# rCSL_sata_001 register map
Vendor: Texas Instruments
Peripheral module from a debugger description file (folder OMAPL138_C6748).
Registers are 32-bit, access not given, reset 0x0 unless marked. A register's access mark holds for its fields unless they carry their own. Offsets are as the file gives them; lines under a group give offsets from that group; [hi:lo] are bit positions; {n}, {i} and the like mark numbered series; 'fields as' and 'values as' point back to an identical list; <NAME> marks a mode.

## SATA (part 1 of 2) — SATA Interface Controller
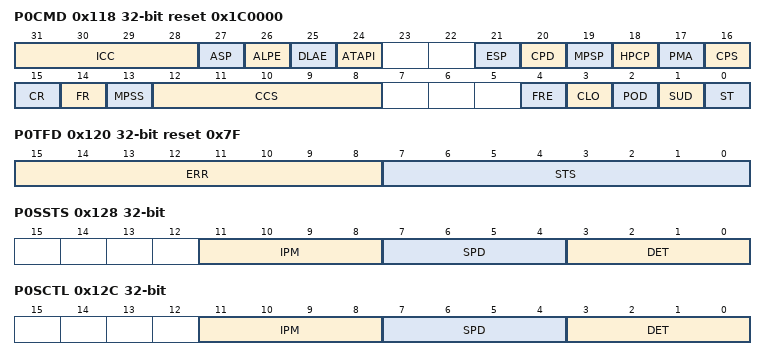
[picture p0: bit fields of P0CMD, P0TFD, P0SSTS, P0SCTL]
0x118 P0CMD reset 0x1C0000 — This register contains bits controlling various Port functions. All RW bits are reset on Global reset.
  [31:28] ICC rw — Interface Communication Control. This field is used to control power management states of the interface. If the Link layer is currently in the L_IDLE state, writes to this field will cause the Port to initiate a transition to the interface power management state requested. If the Link layer is not currently in the L_IDLE state, writes to this field have no effect. " 0xF - 0x7: Reserved " 0x6: Slumber: This will cause the Port to request a transition of the interface to the Slumber state. The SATA device may reject the request and the interface will remain in its current state. " 0x5 - 0x3: Reserved " 0x2: Partial: This will cause the Port to request a transition of the interface to the Partial state. The SATA device may reject the request and the interface will remain in its current state. " 0x1: Active: This will cause the Port to request a transition of the interface into the active state. " 0x0: No-Op/ Idle: When software reads this value, it indicates the Port is ready to accept a new interface control command, although the transition to the previously selected state may not yet have occurred. When system software writes a non-reserved value other than No-Op (0x0), the Port will perform the action and update this field back to Idle (0x0). If software writes to this field to change the state to a state the link is already in (i.e., interface is in the active state and a request is made to go to the active state), the Port will take no action and return this field to Idle. If the interface is in a low power state and software wants to transition to a different low power state, software must first bring the link to active and then initiate the transition to the desired low power
  [27] ASP rw — Aggressive Slumber/Partial. When set to 1, and P0CMD.ALPE=1, the Port will aggressively enter the SLUBMER state when it clears the P0CI and the P0SACT register is cleared or when it clears the P0SACT register and P0CI is cleared. When cleared to 0, and P0CMD.ALPE=1, the Port will aggressively enter the PARTIAL state when it clears the P0CI register and the P0SACT register is cleared when it clears the P0SACT register and P0CI is cleared.
  [26] ALPE rw — Aggressive Link Power Management Enable. When set to 1, the Port will aggressively enter a lower link power state (PARTIAL or SLUMBER) based on the setting of the P#CMD.ASP bit. When cleared to 0, aggressive power management state transition is disabled.
  [25] DLAE rw — Device LED on ATAPI Enable. When set to 1 , the HBA shall drive the LED pin active for commands regardless of the state of P0CMD.ATAPI. When cleared, the HBA shall only drive the LED pin active for commands if P0CMD.ATAPI set to 0 .
  [24] ATAPI rw — Device is ATAPI. When set to '1', the connected device is an ATAPI device. This bit is used by the HBA to control whether or not to generate the desktop LED when commands are active.
  [21] ESP ro — External SATA Port. When set to '1', indicates that this port s signal connector is externally accessible on a signal only connector. When set to '1', CAP.SXS shall be set to '1'. When cleared to 0 , indicates that this port s signal connector is not externally accessible on a signal only connector. ESP is mutually exclusive with the HPCP bit in this register.
  [20] CPD ro — Cold Presence Detection. If set to 1 , the platform supports cold presence detection on this port. If cleared to 0 , the platform does not support cold presence detection on this port. When tis bit is set to '1', P0CMD.HPCP should also be '1'.
  [19] MPSP ro — Mechanical Presence Switch Attached to Port. If set to 1 , the platform supports an mechanical presence switch attached to this port. If cleared to 0 , the platform does not support a mechanical presence switch attached to this port. When this bit is set to 1 , P0CMD.HPCP should also be set to '1'.
  [18] HPCP ro — Hot Plug Capable Port. When set to 1 , indicates that this port s signal and power connectors are externally accessible via a joint signal and power connector for blindmate device hot plug. When cleared to 0 , indicates that this port s signal and power connectors are not externally accessible via a joint signal and power connector.
  [17] PMA rw — Port Multiplier Attached: When set to 1 by software, a Port Multiplier is attached to the HBA for this port. When cleared to 0 by software, a Port Multiplier is not attached to the HBA for this port. Software is responsible for detecting whether a Port Multiplier is present; hardware does not auto-detect the presence of a Port Multiplier.
  [16] CPS ro — Cold Presence State. The CPS bit reports whether a device is currently detected on this port via cold presence detection. If CPS is set to 1 , then the HBA detects via cold presence that a device is attached to this port. If CPS is cleared to 0 , then the HBA detects via cold presence that there is no device attached to this port.
  [15] CR ro — Command List Running. When this bit is set, the command list DMA engine for the port is running.
  [14] FR ro — FIS Receive Running. When this bit is set, the command list DMA engine for the port is running.
  [13] MPSS ro — Mechanical Presence Switch State. The MPSS bit reports the state of a mechanical presence switch attached to this port. If CAP.SMPS is set to 1 and the mechanical presence switch is closed then this bit is cleared to 0 . If CAP.SMPS is set to 1 and the mechanical presence switch is open then this bit is set to 1 . If CAP.SMPS is set to 0 then this bit is cleared to 0 . Software should only use this bit if both CAP.SMPS and P0CMD.MPSP are set to 1'.
  [12:8] CCS ro — Current Command Slot. This field is valid when P0CMD.ST is set to 1 and shall be set to the command slot value of the command that is currently being issued by the HBA. When P0CMD.ST transitions from 1 to 0 , this field shall be reset to 0 . After P0CMD.ST transitions from 0 to 1 , the highest priority slot to issue from next is command slot 0. After the first command has been issued, the highest priority slot to issue from next is P0CMD.CCS + 1. For example, after the HBA has issued its first command, if CCS = 0h and P0CI is set to 3h, the next command that will be issued is from command slot 1.
  [4] FRE rw — FIS Receive Enable. When set, the HBA may post received FISes into the FIS receive area pointed to by P0FB. When cleared, received FISes are not accepted by the HBA, except for the first D2H register FIS after the initialization sequence, and no FISes are posted to the FIS receive area. System software must not set this bit until P0FB have been programmed with a valid pointer to the FIS receive area, and if software wishes to move the base, this bit must first be cleared, and software must wait for the FR bit in this register to be cleared.
  [3] CLO rw — Command List Override. Setting this bit to 1 causes P0TFD.STS.BSY and PxTFD.STS.DRQ to be cleared to 0 . This allows a software reset to be transmitted to the device regardless of whether the BSY and DRQ bits are still set in the P0TFD.STS register. The HBA sets this bit to 0 when P0TFD.STS.BSY and P0TFD.STS.DRQ have been cleared to 0 . A write to this register with a value of 0 shall have no effect. This bit shall only be set to 1 immediately prior to setting the P0CMD.ST bit to 1 from a previous value of 0 . Setting this bit to 1 at any other time is not supported and will result in indeterminate behavior. Software must wait for CLO to be cleared to 0 before setting P0CMD.ST to 1 .
  [2] POD rw — Power On Device. When set, the HBA sets the state of a pin on the HBA to 1 so that it may be used to provide power to a cold-presence detectable port
  [1] SUD rw — Spin-Up Device. On an edge detect from 0 to 1 , the HBA shall start a COMRESET initializatoin sequence to the device. Clearing this bit to 0 does not cause any OOB signal to be sent on the interface. When this bit is leared to 0 and PxSCTL.DET=0h, the HBA will enter listen mode.
  [0] ST rw — Start. When set, the HBA may process the command list. When cleared, the HBA may not process the command list. Whenever this bit is changed from a 0 to a 1 , the HBA starts processing the command list at entry 0 . Whenever this bit is changed from a 1 to a 0 , the P0CI register is cleared by the HBA upon the HBA putting the controller into an idle state. This bit shall only be set to 1 by software after P0CMD.FRE has been set to 1 .
0x120 P0TFD reset 0x7F — This register contains Error and Status registers updated every time a new Register FIS
  [15:8] ERR ro — Contains the latest copy of the task file Error register.
  [7:0] STS ro — Status. Contains the latest copy of the task file Status register: " 7: BSY Indicates the interface is busy " 6-4: n/a Not applicable " 3: DRQ Indicates a data transfer is requested " 2-1: n/a Not Applicable " 0: ERR Indicates an error during the transfer
0x124 P0SIG ro reset 0xFFFFFFFF — This register contains the Device Signature information. It contanis the initial signature of an attached device when the first D2H Register FIS is received from a device. It is updated once after a reset sequence.
  [31:0] SIG — Signature. This field contains the signature received from a device on the first D2H Register FIS. The bit order as is as follows: " 31:24 LBA High (Cylinder High) Register " 23:16 LBA Mid (Cylinder Low) Register " 15:08 LBA Low (Sector Number) Register " 07:00 Sector Count Register This field is updated once after a reset sequence. Reset on Global or Port reset.
0x128 P0SSTS — This 32-bit register conveys the current state of the interface and host.
  [11:8] IPM ro — Interface Power Management. Indicates the current interface state: " 0x0: Device not present or communication not established " 0x1: Interface in active state " 0x2: Interface in Partial power management state " 0x3-0x5: Reserved " 0x6: Interface in Slumber power management state " 0x7-0xF: Reserved
  [7:4] SPD ro — Current Interface Speed. Indicates the negotiated interface communication speed: " 0x0: Device not present or communication not established " 0x1: Generation 1 (1.5Gbps) negotiated " 0x2: Generation 2 (3Gbps) negotiated " 0x3-0xF: Reserved
  [3:0] DET ro — Device Detection. Indicates the interface device detection and PHY state: " 0x0: No device detected and PHY communication not established " 0x1: Device presence detected but PHY communication not established (COMINIT is detected) " 0x2: Reserved " 0x3: Device presence detected and PHY communication established ( PHY Ready is detected) " 0x4: PHY in offline mode as a result of the interface being disabled or running in BIST loopback mode. " 0x5-0xF: Reserved
0x12C P0SCTL — This 32-bit read-write register is used by software to control SATA interface capabilities. Writes to this register result in an action being taken by the Port PHY interface. Reads from the register return the last value written to it. Reset on Global reset. These bits are static and should not be changed frequently due to the clock crossing between the Transport and Link Layers. Software must wait for at least seven periods of the slower clock (clk_asic or vbus clock) before changing this register
  [11:8] IPM rw — Interface Power Management Transitions Allowed. Indicates which power states the Port PHY interface is allowed to transition to. If an interface power management state is disabled, the Port will not initiate that state and any request from the device to enter that state wi ll be rejected via PMNAKp: " 0x0: No interface power management state restrictions " 0x1: Transitions to the Partial state disabled " 0x2: Transitions to the Slumber state disabled " 0x3: Transitions to both Partial and Slumber states disabled " 0x4-0xF: Reserved
  [7:4] SPD rw — Speed Allowed. Indicates the highest allowable speed of the Port PHy interface: " 0x0: No speed negotiation restrictions " 0x1: Limit speed negotiation to Generation 1 (1.5Gbps) communication rate " 0x2: Limit speed negotiation to Generation 2 (3Gbps) communication rate " 0x3-0xF: Reserved Note: When host software must change this field value, the host must also reset the Port (P0SCTL.DET=0x1) at the same time to ensure proper speed negotiation.
  [3:0] DET ro — Device Detection Initialization. Controls the Port s device detection and interface initialization: " 0x0: No device detection or initialization action requested " 0x1: Perform interface initialization sequence to establish communication. This results in the interface being reset and communication re-initialized. " 0x2-0x3: Reserved " 0x4: Disable the Serial ATA interface and put the Port PHY in offline mode. " 0x5-0xF: Reserved Note: This field may only be modified when P0CMD.ST is 0. Changing this field while P0CMD.ST=1 results in undefined behavior. When P0CMD.ST is set to 1, this field should have a value of 0x0.
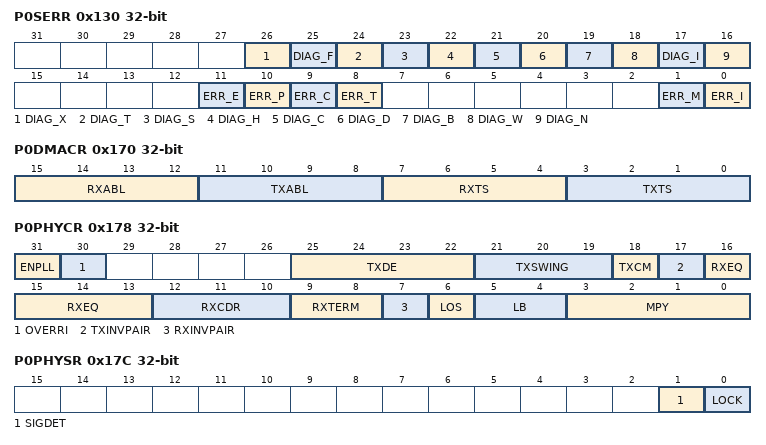
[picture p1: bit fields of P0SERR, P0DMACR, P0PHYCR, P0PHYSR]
0x130 P0SERR — This This 32-bit register represents all the detected interface errors accumulated since the last time it was cleared. The set bits in the SError register indicate that the corresponding error condition became true one or more times since the last time the bit was cleared. The set bits in this register are explicitly cleared by a write operation to the register, Global reset, or Port reset (COMRESET). The value written to clear the set error bits should have ones encoded in the bit positions corresponding to the bits that are to be cleared. All bits in the following table have a reset value of 0
  [26] DIAG_X ro — Exchanged. This field is set to 1 when PHY COMINIT signal is detected. This bit is reflected in the P0IS.PCS bit. Write '1' to Clear this bit field.
  [25] DIAG_F ro — Unknow FIS Type. This field indicates that one or more FISes were received by the Transport layer with good CRC, but had a type field that was not recognized/known and the length was less than or equal to 64 bytes. Write '1' to Clear this bit field. Note: If the Unknown FIS length exceeds 64 bytes, the DIAG_F bit is not set and the DIAG_T bit is set instead.
  [24] DIAG_T ro — Transport State Transition Error. This field indicates that a Transport Layer protocol violation was detected. Write '1' to Clear this bit field.
  [23] DIAG_S ro — Link Sequence Error.This field indicates that one or more Link state machine error conditions was encountered. One of the conditions that cause this bit to be set is device doing SYNC escape during FIS transmission. Write '1' to Clear this bit field.
  [22] DIAG_H ro — Handshake Error. This field indications that one or more R-ERRp was received in response to frame transmission. Such errors may be the result of a CRC error detected by the device, a disparity or 8b/10b decoding error, or other error condition leading to a negative handshake on a transmitted frame. Write '1' to Clear this bit field.
  [21] DIAG_C ro — CRC Error. This field indicates that one ore more CRC errors were detected by the Link layer during FIS reception Write '1' to Clear this bit field.
  [20] DIAG_D ro — Disparity Error. This field is always 0 since it isn t used by the AHCI specification. Write '1' to Clear this bit field.
  [19] DIAG_B ro — 10B to to 8B Decode Error. This field indicates Decode errors were detected by 10b8b decoder. Write '1' to Clear this bit field Note: This bit is set only when an error is detected on the received FIS data word. This bit is not set when an error is detected on the primitive, regardless of whether it is inside or outside the FIS.
  [18] DIAG_W ro — Comm Wake. This bit is set when the PHY COMWAKE signal is detected. Write '1' to Clear this bit field.
  [17] DIAG_I ro — PHY Internal Error. This bit is set when the PHY detects some internal error. Write '1' to Clear this bit field. Note: The TI phy does not support any errors so this bit will never be set
  [16] DIAG_N ro — PHYReady Change. This bit indicates that the PHY Ready signal changed state. This bit is reflected in the P0IS.PRCS bit. Write '1' to Clear this bit field.
  [11] ERR_E ro — Internal Error. This bit is set to 1 when one or more AHB bus ERROR responses are detected on the master or the slave interfaces. Write '1' to Clear this bit field.
  [10] ERR_P ro — Protocol Error. This bit is set to 1 when any of the following conditions are detected: " Transport state transition error (DIAG_T) " Link sequence error (DIAG_S) " RxFIFO overflow " Link bad end error (WTRM instead of EOF is received). Write '1' to Clear this bit field.
  [9] ERR_C ro — Non-Recovered Persistent Communication Error. This bit is set to 1 when PHY Ready signal is negated due to the loss of communication with the device or problems with the interface, but not after transition from active to Partial or Slumber power management state. Write '1' to Clear this bit field.
  [8] ERR_T ro — Non-Recovered Transient Data Integrity Error. This bit is set if any of the following P#SERR register bits is set during Data FIS transfer: " ERR_P (Protocol) " DIAG_C (CRC) " DIAG_H (Handshake) " ERR_C ( PHY Ready negation) Write '1' to Clear this bit field.
  [1] ERR_M ro — Recovered Communication Error. This bit is set to 1 when PHY Ready condition is detected after interface initialization, but not after transition from partial or Slumber power management state to active state. Write '1' to Clear this bit field.
  [0] ERR_I ro — Recovered Data Integrity. This bit is set if any of the following P#SERR register bits is set during non-Data FIS transfer: " ERR_P (Protocol) " DIAG_C (CRC) " DIAG_H (Handshake) " ERR_C ( PHY Ready negation) Write '1' to Clear this bit field.
0x134 P0SACT rw — This register is used to indicate what command slots have commands in them when issuing native queued command.
  [31:0] DS — Device Status. This field is bit significant. Each bit corresponds to the TAG and command slot of a native queued command, where bit 0 corresponds to TAG 0 and command slot 0. This field is set by software prior to issuing a native queued command for a particular command slot. Prior to writing P0CI[TAG] to 1 , software will set DS[TAG] to 1 to indicate that a command with that TAG is outstanding. The device clears bits in this field by sending a Set Device Bits FIS to the host. The HBA clears bits in this field that are set to 1 in the SActive field of the Set Device Bits FIS. The HBA only clears bits that correspond to native queued commands that have completed successfully. Software should only write this field when P0CMD.ST is set to 1 . This field is cleared when P0CMD.ST is written from a 1 to a 0 by software. This field is not cleared by a COMRESET or a software reset.
0x138 P0CI rw — This register is used to indicate what that a command has been constructed and may be carried out
  [31:0] CI — Command Issued. This field is bit significant. Each bit corresponds to a command slot, where bit 0 corresponds to command slot 0. This field is set by software to indicate to the Port that a command has been built in system memory for a command slot and may be sent to the device. When the Port receives a FIS which clears the BSY, DRQ, and ERR bits for the command, it clears the corresponding bit in this register for that command slot. Bits in this field can only be set to 1 by software when P0CMD.ST is set to 1.
0x13C P0SNTF — This register is used to determine if asynchronous notification events have occurred for directly connected devices and devices connected to a Port Multiplier
  [15:0] PMN ro — PM Notify. This field indicates whether a particular device with the corresponding PM Port number issued a Set Device Bits FIS to the SATASS Port with the Notification bit set: " PM Port 0h sets bit 0 " PM Port 0h sets bit 1 " Etc & Individual bits are cleared by software writing 1s to the corresponding bit positions. This field is reset on Global reset, but it is not reset by Port reset (COMRESET) or software reset. Wrte '1' to Clear this bit field.
0x170 P0DMACR — This register contains bits for controlling the Port DMA engine.
  [15:12] RXABL rw — Receive Burst Limit. This field allows software to limit the VBUSP master write burst size: " 0x0, 0x5-0xF: " 0x1: Limit VBUSP Burst size to 1 DWORD " 0x2: Limit VBUSP Burst size to 2 DWORDs " 0x3: Limit VBUSP Burst size to 4 DWORDs " 0x4: Limit VBUSP Burst size to 8 DWORDs Note: SATASS master breaks the burst at 1Kbyte address boundaries regardless of the RXABL value. Note: This field is read-write when P#CMD.ST=0 and read-only when P0CMD.ST=1.
  [11:8] TXABL rw — Transmit Burst Limit. This field allows software to limit the VBUSP master read burst size: " 0x0, 0x5-0xF: " 0x1: Limit VBUSP Burst size to 1 DWORD " 0x2: Limit VBUSP Burst size to 2 DWORDs " 0x3: Limit VBUSP Burst size to 4 DWORDs " 0x4: Limit VBUSP Burst size to 8 DWORDs Note: SATASS master breaks the burst at 1Kbyte address boundaries regardless of the TXABL value. Note: This field is read-write when P0CMD.ST=0 and read-only when P0CMD.ST=1.
  [7:4] RXTS rw — Receive Transaction Size (RX_TRANSACTION_SIZE). This field defines the Port DMA transaction size in DWORDs for receive (system bus write, device read) operation: " 0x0: 1 DWORD " 0x1: 2 DWORDs " 0x2: 4 DWORDs " 0x3 - 0xF: 8 DWORDs This field is RW when P0CMD.ST=0 and RO when P0CMD.ST=1.
  [3:0] TXTS rw — Receive Transaction Size (TX_TRANSACTION_SIZE). This field defines the Port DMA transaction size in DWORDs for transmit (system bus read, device write) operation: " 0x0: 1 DWORD " 0x1: 2 DWORDs " 0x2: 4 DWORDs " 0x3 - 0xF: 8 DWORDs This field is RW when P0CMD.ST=0 and RO when P0CMD.ST=1.
0x178 P0PHYCR — ThisPort PHY Control Register This register is used to control the PHY. These ports are configured for the WIZ6C2B2N5W0M (Maverick B2) macro. Refer to that spec for further details. Note: This description is only valid for configuration GS60 (Table 1 Sub-system Configurations). See corresponding P0PHYSR Register description for each configuration.
  [31] ENPLL rw — Enable Phy PLL. This bit must be written to 1 to enable the phy s PLL and use the link. " 0 Disabled " 1 - Enabled Note: This must be enabled by software before initialization is started on the device. Note: This bit should not be enabled unless the MPY field has been previously set or is being set in the same write. Changing the MPY field while the PLL is enabled disrupts the link clocks and may disrupt the link, requiring a port reset to fix Note: The PLL may be turned off while the link is in a low power state (Partial or Slumber). If it is, then it must be re-enabled ~1us + 200 refclock cycles before software attempts to remove the low power state. WARNING: If the PLL is disabled in a low power state, the SATASS cannot wake up from low power based on a device request. If the device requests wakeup and the SATASS does not respond, a port reset may be required after software re-enables the PLL and removes the low power state. Caution should be taken to never disable the PLL if it is possible that the device will request a wakeup from low power.
  [30] OVERRI rw — Override for Clock Stopping. Normally the functional clock can only be stopped if the link is put into partial or slumber power mode. However, if there is no device attached (such as in a removable media situation) the user may wish to stop the functional clocks but not be able to enter a low power state. In this case, software can set the OVERRIDE bit to 1, removing the requirement for a low power state " 0 Normal " 1 Override WARNING: If there is a device attached, the OVERRIDE bit is used, and the functional clock is stopped when the link is not in a low power state it will ruin the link and cause undetermined behavior. A port reset or full SATASS reset may be required to recover.
  [25:22] TXDE rw — The Transmitter De-emphasis. Select one of 16 output de-emphasis settings from 0 to 71.42%. Note: Request Table associating parameters with percentage of reduction as well magnitue of reduction in DB.
  [21:19] TXSWING rw — Transmitter Output Swing. Selects one of 8 output amplitude settings between 125 and 1375mV(dfpp). Note: Request Table associating parameters with Amplitude settings.
  [18] TXCM rw — Transmitter Common Mode. Adjusts the common mode to suit the termination at the attached receiver. " 0 Normal Common Mode " 1 Raised common mode. Common mode raised by 5% of e54
  [17] TXINVPAIR rw — Transmitter Invert Polarity. Inverts the polarity of TXP0 and TXN0
  [16:13] RXEQ rw — Receiver Equalizer. Enables and configures the adaptive equalizer to compensate for loss in the transmission media. Note: Request Table for associating parameters with gain type and value.
  [12:10] RXCDR rw — Receiver Clock/data Recovery. Note: Request Table for associating parameters.
  [9:8] RXTERM rw — Reciver Termination. Selects input termination options suitable for a variety of AC or DC coupled scenarios. Note: Request Table for associating parameters.
  [7] RXINVPAIR rw — Receiver Invert Polarity. Inverts the polarity of RXP0 and RXN0
  [6] LOS rw — Loss of Signal Detection. Disables or Enables Loss of Signal detection which is necessary for Receive Data and OOB Detection " 0 Disabled " 1 Enabled Note: This must be enabled by software before initialization is started on the device.
  [5:4] LB rw — Loop Bandwidth. Specifi loop bandewidth settings. Note: " Request Table for associating parameters. " In systems with more than 1 Port, only Port0 (P0) has this field connected. In all other pts, the filedld is writable but will have no effect.
  [3:0] MPY rw — PLL Multiply. Select PLL multiply factors between 4 and 60. Note: Request Table for associating parameters.
0x17C P0PHYSR — This register is used to reflect the PHY status
  [1] SIGDET ro — Signal Detect. Indicates that Port # has a signal present.
  [0] LOCK ro — PLL Lock. Indicates that the PLL has locked.
